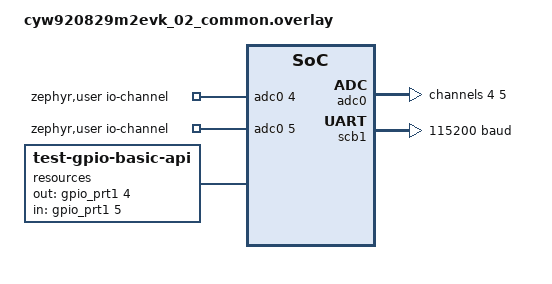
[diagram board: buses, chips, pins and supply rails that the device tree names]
/*
 * Copyright (c) 2024 Infineon Technologies AG,
 * or an affiliate of Infineon Technologies AG.
 *
 * SPDX-License-Identifier: Apache-2.0
 */

tst_dma0: &dma0 {
	status = "okay";
};

#include <zephyr/dt-bindings/adc/adc.h>

/ {
	zephyr,user {
		io-channels = <&adc0 4>, <&adc0 5>;
	};
};

&adc0 {
	status = "okay";
	#address-cells = <1>;
	#size-cells = <0>;
	channel@4 {
		reg = <4>;
		zephyr,acquisition-time = <ADC_ACQ_TIME(ADC_ACQ_TIME_MICROSECONDS, 1)>;
		zephyr,gain = "ADC_GAIN_1";
		zephyr,reference = "ADC_REF_INTERNAL";
		zephyr,resolution = <16>;
		zephyr,input-positive = <4>;
	};
	channel@5 {
		reg = <5>;
		zephyr,acquisition-time = <ADC_ACQ_TIME(ADC_ACQ_TIME_MICROSECONDS, 1)>;
		zephyr,gain = "ADC_GAIN_1";
		zephyr,reference = "ADC_REF_INTERNAL";
		zephyr,resolution = <16>;
		zephyr,input-positive = <5>;
	};
};

/ {
	resources {
		compatible = "test-gpio-basic-api";
		out-gpios = <&gpio_prt1 4 0>;
		in-gpios = <&gpio_prt1 5 0>;
	};
};

&dma0 {
	#address-cells = <1>;
	#size-cells = <0>;
	compatible = "infineon,dma";
	status = "okay";
};

dut: &scb1 {
	compatible = "infineon,uart";
	status = "okay";
	current-speed = <115200>;
	dmas = <&dma0 6>, <&dma0 7>;
	dma-names = "tx", "rx";
	pinctrl-0 = <&p1_3_scb1_uart_tx &p1_2_scb1_uart_rx>;
	pinctrl-names = "default";
};

&p1_3_scb1_uart_tx {
	drive-push-pull;
};

&p1_2_scb1_uart_rx {
	input-enable;
};
